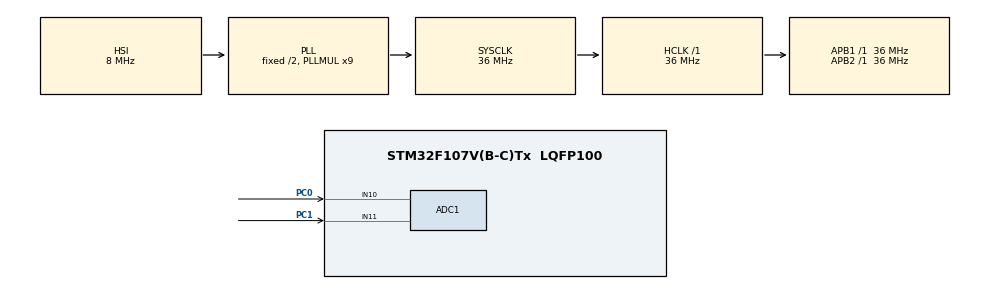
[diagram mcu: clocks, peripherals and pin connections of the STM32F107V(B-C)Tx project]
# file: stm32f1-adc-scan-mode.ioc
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Mcu.Family=STM32F1
ADC1.Rank-0\#ChannelRegularConversion=1
ADC1.ContinuousConvMode=ENABLE
PC0.Signal=ADCx_IN10
RCC.SYSCLKSource=RCC_SYSCLKSOURCE_PLLCLK
ProjectManager.StackSize=0x400
RCC.ADCPresc=RCC_ADCPCLK2_DIV4
PA13.Signal=SYS_JTMS-SWDIO
ProjectManager.TargetToolchain=STM32CubeIDE
RCC.HCLKFreq_Value=36000000
RCC.APB2TimFreq_Value=36000000
ADC1.Channel-1\#ChannelRegularConversion=ADC_CHANNEL_11
RCC.USBFreq_Value=24000000
RCC.AHBFreq_Value=36000000
ADC1.Channel-0\#ChannelRegularConversion=ADC_CHANNEL_10
board=custom
RCC.PLLMUL=RCC_PLL_MUL9
RCC.APB2Freq_Value=36000000
SH.ADCx_IN11.0=ADC1_IN11,IN11
PA14.Mode=Serial_Wire
ADC1.NbrOfConversion=2
PA13.Mode=Serial_Wire
Mcu.Name=STM32F107V(B-C)Tx
ADC1.SamplingTime-0\#ChannelRegularConversion=ADC_SAMPLETIME_1CYCLE_5
ADC1.SamplingTime-1\#ChannelRegularConversion=ADC_SAMPLETIME_1CYCLE_5
RCC.SYSCLKFreq_VALUE=36000000
Mcu.Package=LQFP100
ADC1.master=1
ADC1.Rank-1\#ChannelRegularConversion=2
PA14.Signal=SYS_JTCK-SWCLK
SH.ADCx_IN10.0=ADC1_IN10,IN10
ProjectManager.HeapSize=0x200
NVIC.PriorityGroup=NVIC_PRIORITYGROUP_4
ADC1.NbrOfConversionFlag=1
RCC.APB1TimFreq_Value=36000000
RCC.APB1Freq_Value=36000000
PC1.Signal=ADCx_IN11

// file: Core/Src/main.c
/* USER CODE BEGIN Header */
/**
  ******************************************************************************
  * @file           : main.c
  * @brief          : Main program body
  ******************************************************************************
  * @attention
  *
  * <h2><center>&copy; Copyright (c) 2021 STMicroelectronics.
  * All rights reserved.</center></h2>
  *
  * This software component is licensed by ST under BSD 3-Clause license,
  * the "License"; You may not use this file except in compliance with the
  * License. You may obtain a copy of the License at:
  *                        opensource.org/licenses/BSD-3-Clause
  *
  ******************************************************************************
  */
/* USER CODE END Header */
#include "main.h"

ADC_HandleTypeDef hadc1;

void SystemClock_Config(void);
static void MX_GPIO_Init(void);
static void MX_ADC1_Init(void);
/* USER CODE BEGIN PFP */
void ADC_Select_CH10 (void);
void ADC_Select_CH11 (void);
/* USER CODE END PFP */

/* USER CODE BEGIN 0 */
uint32_t ADC_VAL;
uint32_t ADC_VAL2;
/* USER CODE END 0 */

int main(void)
{

  /* MCU Configuration--------------------------------------------------------*/

  /* Reset of all peripherals, Initializes the Flash interface and the Systick. */
  HAL_Init();

  /* Configure the system clock */
  SystemClock_Config();

  /* Initialize all configured peripherals */
  MX_GPIO_Init();
  MX_ADC1_Init();

  /* Infinite loop */
  /* USER CODE BEGIN WHILE */
  while (1)
  {
	ADC_Select_CH10();
	HAL_ADC_Start(&hadc1);
	HAL_ADC_PollForConversion(&hadc1, 1000);
	ADC_VAL = HAL_ADC_GetValue(&hadc1);
	HAL_ADC_Stop(&hadc1);
	HAL_Delay(100);
	ADC_Select_CH11();
	HAL_ADC_Start(&hadc1);
	HAL_ADC_PollForConversion(&hadc1, 1000);
	ADC_VAL2 = HAL_ADC_GetValue(&hadc1);
	HAL_ADC_Stop(&hadc1);
	HAL_Delay(100);
    /* USER CODE END WHILE */

  }
}

void SystemClock_Config(void)
{
  RCC_OscInitTypeDef RCC_OscInitStruct = {0};
  RCC_ClkInitTypeDef RCC_ClkInitStruct = {0};
  RCC_PeriphCLKInitTypeDef PeriphClkInit = {0};

  /** Initializes the RCC Oscillators according to the specified parameters
  * in the RCC_OscInitTypeDef structure.
  */
  RCC_OscInitStruct.OscillatorType = RCC_OSCILLATORTYPE_HSI;
  RCC_OscInitStruct.HSIState = RCC_HSI_ON;
  RCC_OscInitStruct.HSICalibrationValue = RCC_HSICALIBRATION_DEFAULT;
  RCC_OscInitStruct.Prediv1Source = RCC_PREDIV1_SOURCE_HSE;
  RCC_OscInitStruct.PLL.PLLState = RCC_PLL_ON;
  RCC_OscInitStruct.PLL.PLLSource = RCC_PLLSOURCE_HSI_DIV2;
  RCC_OscInitStruct.PLL.PLLMUL = RCC_PLL_MUL9;
  RCC_OscInitStruct.PLL2.PLL2State = RCC_PLL_NONE;
  if (HAL_RCC_OscConfig(&RCC_OscInitStruct) != HAL_OK)
  {
    Error_Handler();
  }
  /** Initializes the CPU, AHB and APB buses clocks
  */
  RCC_ClkInitStruct.ClockType = RCC_CLOCKTYPE_HCLK|RCC_CLOCKTYPE_SYSCLK
                              |RCC_CLOCKTYPE_PCLK1|RCC_CLOCKTYPE_PCLK2;
  RCC_ClkInitStruct.SYSCLKSource = RCC_SYSCLKSOURCE_PLLCLK;
  RCC_ClkInitStruct.AHBCLKDivider = RCC_SYSCLK_DIV1;
  RCC_ClkInitStruct.APB1CLKDivider = RCC_HCLK_DIV1;
  RCC_ClkInitStruct.APB2CLKDivider = RCC_HCLK_DIV1;

  if (HAL_RCC_ClockConfig(&RCC_ClkInitStruct, FLASH_LATENCY_1) != HAL_OK)
  {
    Error_Handler();
  }
  PeriphClkInit.PeriphClockSelection = RCC_PERIPHCLK_ADC;
  PeriphClkInit.AdcClockSelection = RCC_ADCPCLK2_DIV4;
  if (HAL_RCCEx_PeriphCLKConfig(&PeriphClkInit) != HAL_OK)
  {
    Error_Handler();
  }
  /** Configure the Systick interrupt time
  */
  __HAL_RCC_PLLI2S_ENABLE();
}

static void MX_ADC1_Init(void)
{

  ADC_ChannelConfTypeDef sConfig = {0};

  /** Common config
  */
  hadc1.Instance = ADC1;
  hadc1.Init.ScanConvMode = ADC_SCAN_ENABLE;
  hadc1.Init.ContinuousConvMode = ENABLE;
  hadc1.Init.DiscontinuousConvMode = DISABLE;
  hadc1.Init.ExternalTrigConv = ADC_SOFTWARE_START;
  hadc1.Init.DataAlign = ADC_DATAALIGN_RIGHT;
  hadc1.Init.NbrOfConversion = 2;
  if (HAL_ADC_Init(&hadc1) != HAL_OK)
  {
    Error_Handler();
  }
  /** Configure Regular Channel
  */
  sConfig.Channel = ADC_CHANNEL_10;
  sConfig.Rank = ADC_REGULAR_RANK_1;
  sConfig.SamplingTime = ADC_SAMPLETIME_1CYCLE_5;
  if (HAL_ADC_ConfigChannel(&hadc1, &sConfig) != HAL_OK)
  {
    Error_Handler();
  }
  /** Configure Regular Channel
  */
  sConfig.Channel = ADC_CHANNEL_11;
  sConfig.Rank = ADC_REGULAR_RANK_2;
  if (HAL_ADC_ConfigChannel(&hadc1, &sConfig) != HAL_OK)
  {
    Error_Handler();
  }

}

static void MX_GPIO_Init(void)
{

  /* GPIO Ports Clock Enable */
  __HAL_RCC_GPIOC_CLK_ENABLE();
  __HAL_RCC_GPIOA_CLK_ENABLE();

}

/* USER CODE BEGIN 4 */
void ADC_Select_CH10 (void)
{
 ADC_ChannelConfTypeDef sConfig = {0};
 sConfig.Channel = ADC_CHANNEL_10;
 sConfig.Rank = ADC_REGULAR_RANK_1;
 sConfig.SamplingTime = ADC_SAMPLETIME_1CYCLE_5;
 if (HAL_ADC_ConfigChannel(&hadc1, &sConfig) != HAL_OK)
 {
   Error_Handler();
 }
}
void ADC_Select_CH11 (void)
{
 ADC_ChannelConfTypeDef sConfig = {0};
 sConfig.Channel = ADC_CHANNEL_11;
 sConfig.Rank = ADC_REGULAR_RANK_1;
 sConfig.SamplingTime = ADC_SAMPLETIME_1CYCLE_5;
 if (HAL_ADC_ConfigChannel(&hadc1, &sConfig) != HAL_OK)
 {
   Error_Handler();
 }
}
/* USER CODE END 4 */

void Error_Handler(void)
{
  __disable_irq();
  while (1)
  {
  }
}

/************************ (C) COPYRIGHT STMicroelectronics *****END OF FILE****/
